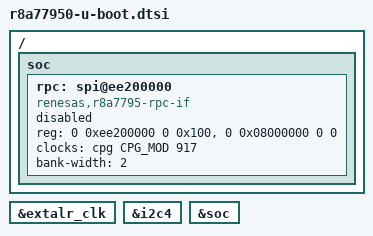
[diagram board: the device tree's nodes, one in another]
// SPDX-License-Identifier: GPL-2.0
/*
 * Device Tree Source extras for U-Boot on RCar R8A7795 SoC
 *
 * Copyright (C) 2018 Marek Vasut <marek.vasut@gmail.com>
 */

#include "r8a779x-u-boot.dtsi"

&extalr_clk {
	bootph-all;
};

/ {
	soc {
		rpc: spi@ee200000 {
			compatible = "renesas,r8a7795-rpc-if", "renesas,rcar-gen3-rpc-if";
			reg = <0 0xee200000 0 0x100>, <0 0x08000000 0 0>;
			clocks = <&cpg CPG_MOD 917>;
			bank-width = <2>;
			status = "disabled";
		};
	};
};

/delete-node/ &ak4613;
/delete-node/ &audma0;
/delete-node/ &audma1;
/delete-node/ &can0;
/delete-node/ &can1;
/delete-node/ &canfd;
/delete-node/ &csi20;
/delete-node/ &csi21;
/delete-node/ &csi40;
/delete-node/ &csi41;
/delete-node/ &drif00;
/delete-node/ &drif01;
/delete-node/ &drif10;
/delete-node/ &drif11;
/delete-node/ &drif20;
/delete-node/ &drif21;
/delete-node/ &drif30;
/delete-node/ &drif31;
/delete-node/ &du;
/delete-node/ &fcpf0;
/delete-node/ &fcpf1;
/delete-node/ &fcpf2;
/delete-node/ &fcpvb0;
/delete-node/ &fcpvb1;
/delete-node/ &fcpvd0;
/delete-node/ &fcpvd1;
/delete-node/ &fcpvd2;
/delete-node/ &fcpvd3;
/delete-node/ &fcpvi0;
/delete-node/ &fcpvi1;
/delete-node/ &fcpvi2;
/delete-node/ &hdmi0;
/delete-node/ &hdmi1;
/delete-node/ &lvds0;
/delete-node/ &rcar_sound;
/delete-node/ &sound_card;
/delete-node/ &vin0;
/delete-node/ &vin1;
/delete-node/ &vin2;
/delete-node/ &vin3;
/delete-node/ &vin4;
/delete-node/ &vin5;
/delete-node/ &vin6;
/delete-node/ &vin7;
/delete-node/ &vspbc;
/delete-node/ &vspbd;
/delete-node/ &vspd0;
/delete-node/ &vspd1;
/delete-node/ &vspd2;
/delete-node/ &vspd3;
/delete-node/ &vspi0;
/delete-node/ &vspi1;
/delete-node/ &vspi2;

/ {
	/delete-node/ cvbs-in;
	/delete-node/ hdmi-in;
	/delete-node/ hdmi0-out;
	/delete-node/ hdmi1-out;
	/delete-node/ vga-encoder;
	/delete-node/ vga;
};

&i2c4 {
	/delete-node/ video-receiver@70;
};

&soc {
	/delete-node/ fdp1@fe940000;
	/delete-node/ fdp1@fe944000;
	/delete-node/ fdp1@fe948000;
	/delete-node/ imr-lx4@fe860000;
	/delete-node/ imr-lx4@fe870000;
	/delete-node/ imr-lx4@fe880000;
	/delete-node/ imr-lx4@fe890000;
};
